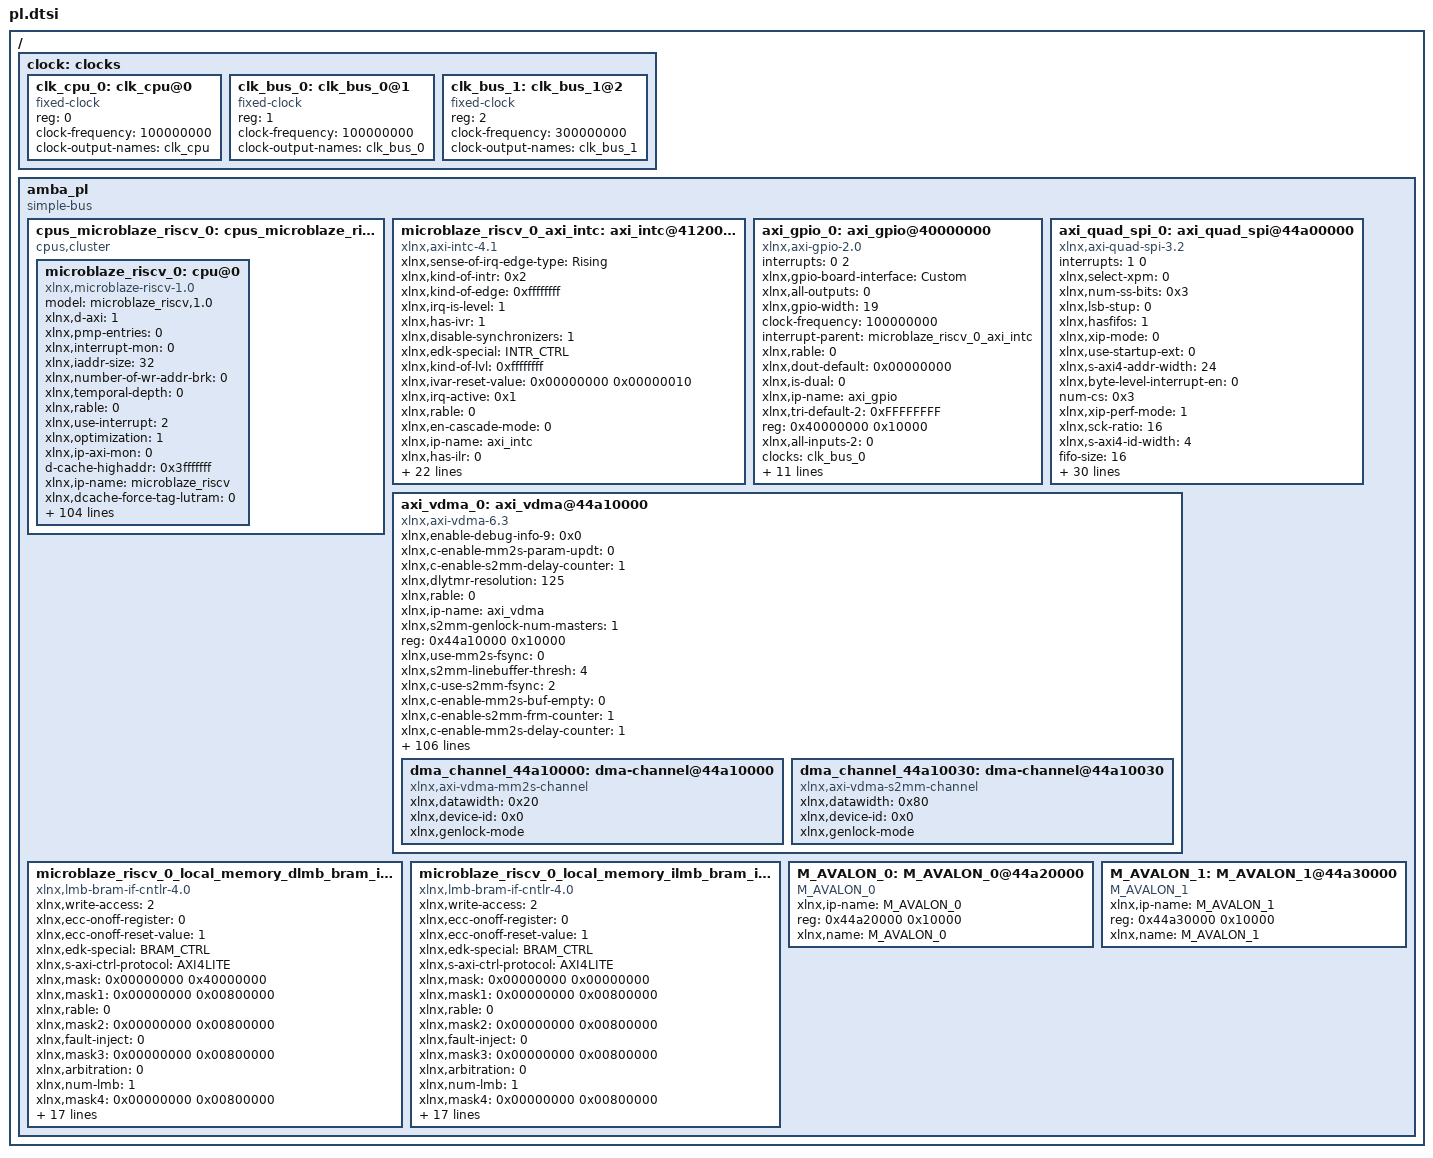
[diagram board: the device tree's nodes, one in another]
/ {
	clock: clocks {
		#address-cells = <1>;
		#size-cells = <0>;
		clk_cpu_0: clk_cpu@0 {
			compatible = "fixed-clock";
			reg = <0>;
			clock-frequency = <100000000>;
			clock-output-names = "clk_cpu";
			#clock-cells = <0>;
		};
		clk_bus_0: clk_bus_0@1 {
			compatible = "fixed-clock";
			reg = <1>;
			clock-frequency = <100000000>;
			clock-output-names = "clk_bus_0";
			#clock-cells = <0>;
		};
		clk_bus_1: clk_bus_1@2 {
			compatible = "fixed-clock";
			reg = <2>;
			clock-frequency = <300000000>;
			clock-output-names = "clk_bus_1";
			#clock-cells = <0>;
		};
	};
	amba_pl: amba_pl {
		ranges;
		compatible = "simple-bus";
		#address-cells = <1>;
		#size-cells = <1>;
		cpus_microblaze_riscv_0: cpus_microblaze_riscv@0 {
			#cpu-mask-cells = <1>;
			compatible = "cpus,cluster";
			#address-cells = <1>;
			#size-cells = <0>;
			microblaze_riscv_0: cpu@0 {
				model = "microblaze_riscv,1.0";
				xlnx,d-axi = <1>;
				xlnx,pmp-entries = <0>;
				xlnx,interrupt-mon = <0>;
				xlnx,iaddr-size = <32>;
				xlnx,number-of-wr-addr-brk = <0>;
				xlnx,temporal-depth = <0>;
				xlnx,rable = <0>;
				xlnx,use-interrupt = <2>;
				xlnx,optimization = <1>;
				xlnx,ip-axi-mon = <0>;
				d-cache-highaddr = <0x3fffffff>;
				xlnx,ip-name = "microblaze_riscv";
				xlnx,dcache-force-tag-lutram = <0>;
				xlnx,pc-width = <15>;
				xlnx,interrupt-is-edge = <0>;
				reg = <0x0>;
				xlnx,async-interrupt = <1>;
				xlnx,use-mmu = <0>;
				xlnx,icache-victims = <0>;
				xlnx,use-bitman-a = <0>;
				xlnx,d-lmb-mon = <0>;
				xlnx,d-lmb-protocol = <0>;
				xlnx,use-bitman-b = <0>;
				xlnx,use-bitman-c = <0>;
				xlnx,dc-axi-mon = <0>;
				xlnx,debug-trace-async-reset = <0>;
				xlnx,trace = <0>;
				xlnx,part = "xcau25p-ffvb676-2-e";
				xlnx,use-config-reset = <0>;
				xlnx,i-lmb-mon = <0>;
				xlnx,dcache-byte-size = <4096>;
				xlnx,ill-instr-exception = <2>;
				compatible = "xlnx,microblaze-riscv-1.0" , "xlnx,microblaze_riscv";
				xlnx,data-size = <32>;
				xlnx,fault-tolerant = <1>;
				xlnx,use-sleep = <0>;
				xlnx,debug-trace-size = <8192>;
				xlnx,pmp-granularity = <2>;
				xlnx,mmu-privileged-instr = <0>;
				d-cache-line-size = <16>;
				xlnx,d-lmb = <1>;
				xlnx,enable-discrete-ports = <0>;
				clock-frequency = <100000000>;
				xlnx,debug-interface = <0>;
				xlnx,use-ext-brk = <0>;
				xlnx,daddr-size = <32>;
				xlnx,debug-enabled = <1>;
				xlnx,num-sync-ff-dbg-trace-clk = <2>;
				xlnx,i-lmb-protocol = <0>;
				xlnx,fsl-exception = <0>;
				xlnx,use-extended-fsl-instr = <0>;
				xlnx,dp-axi-mon = <0>;
				xlnx,impid = <0x00000000 0x00000001>;
				xlnx,branch-target-cache-size = <0>;
				xlnx,dcache-use-writeback = <0>;
				xlnx,use-bitman-s = <0>;
				bus-handle = <&amba_pl>;
				xlnx,icache-line-len = <4>;
				xlnx,base-vectors = <0x00000000 0x00000000>;
				xlnx,ecc-use-ce-exception = <0>;
				xlnx,use-dcache = <0>;
				xlnx,use-barrel = <1>;
				xlnx,edk-special = "microblaze_riscv";
				xlnx,use-muldiv = <2>;
				xlnx,addr-size = <32>;
				xlnx,debug-external-trace = <0>;
				xlnx,piaddr-size = <32>;
				xlnx,misaligned-exceptions = <1>;
				xlnx,use-bitman = <0>;
				xlnx,num-sync-ff-clk-debug = <2>;
				xlnx,debug-event-counters = <0>;
				xlnx,use-atomic = <0>;
				xlnx,i-axi = <0>;
				xlnx,icache-streams = <0>;
				xlnx,g-template-list = <1>;
				xlnx,dcache-line-len = <4>;
				xlnx,num-sync-ff-clk = <2>;
				xlnx,num-sync-ff-dbg-clk = <1>;
				xlnx,interconnect = <2>;
				xlnx,hartid = <0x00000000 0x00000000>;
				xlnx,debug-latency-counters = <0>;
				xlnx,edk-iptype = "PROCESSOR";
				xlnx,use-fpu = <0>;
				xlnx,icache-byte-size = <8192>;
				xlnx,edge-is-positive = <1>;
				xlnx,use-icache = <0>;
				d-cache-size = <4096>;
				xlnx,async-wakeup = <3>;
				xlnx,use-non-secure = <0>;
				xlnx,number-of-rd-addr-brk = <0>;
				d-cache-baseaddr = <0x00000000>;
				xlnx,use-compression = <1>;
				xlnx,avoid-primitives = <0>;
				xlnx,use-counters = <1>;
				xlnx,lockstep-slave = <0>;
				xlnx,use-ext-nm-brk = <0>;
				xlnx,pdaddr-size = <32>;
				xlnx,instr-size = <32>;
				interrupt-handle = <&microblaze_riscv_0_axi_intc>;
				xlnx,i-lmb = <1>;
				xlnx,lockstep-select = <0>;
				xlnx,lmb-data-size = <32>;
				xlnx,ic-axi-mon = <0>;
				xlnx,num-sync-ff-clk-irq = <1>;
				xlnx,fsl-links = <0>;
				timebase-frequency = <100000000>;
				xlnx,archid = <0x00000000 0x00000001>;
				xlnx,icache-force-tag-lutram = <0>;
				xlnx,dcache-data-width = <0>;
				xlnx,dcache-victims = <0>;
				xlnx,use-branch-target-cache = <0>;
				xlnx,debug-profile-size = <0>;
				xlnx,lockstep-master = <0>;
				xlnx,freq = <100000000>;
				xlnx,number-of-pc-brk = <1>;
				xlnx,imprecise-exceptions = <0>;
				xlnx,icache-data-width = <0>;
				xlnx,debug-counter-width = <64>;
			};
		};
		microblaze_riscv_0_axi_intc: axi_intc@41200000 {
			#interrupt-cells = <2>;
			xlnx,sense-of-irq-edge-type = "Rising";
			xlnx,kind-of-intr = <0x2>;
			xlnx,kind-of-edge = <0xffffffff>;
			xlnx,irq-is-level = <1>;
			xlnx,has-ivr = <1>;
			compatible = "xlnx,axi-intc-4.1" , "xlnx,xps-intc-1.00.a";
			xlnx,disable-synchronizers = <1>;
			xlnx,edk-special = "INTR_CTRL";
			xlnx,kind-of-lvl = <0xffffffff>;
			xlnx,ivar-reset-value = <0x00000000 0x00000010>;
			xlnx,irq-active = <0x1>;
			xlnx,rable = <0>;
			xlnx,en-cascade-mode = <0>;
			xlnx,ip-name = "axi_intc";
			xlnx,has-ilr = <0>;
			reg = <0x41200000 0x10000>;
			xlnx,addr-width = <0x20>;
			xlnx,s-axi-aclk-freq-mhz = <100>;
			xlnx,num-sw-intr = <0>;
			xlnx,irq-connection = <0>;
			xlnx,num-intr-inputs = <0x2>;
			xlnx,has-sie = <1>;
			xlnx,has-cie = <1>;
			xlnx,enable-async = <0>;
			xlnx,num-sync-ff = <2>;
			xlnx,mb-clk-not-connected = <1>;
			xlnx,has-ipr = <1>;
			xlnx,edk-iptype = "PERIPHERAL";
			xlnx,sense-of-irq-level-type = "Active_High";
			xlnx,cascade-master = <0>;
			xlnx,processor-clk-freq-mhz = <100>;
			status = "okay";
			xlnx,is-fast = <0x1>;
			xlnx,has-fast = <1>;
			xlnx,ivar-rst-val = <0x0000000000000010>;
			interrupt-controller;
			xlnx,async-intr = <0xFFFFFFFC>;
			xlnx,name = "microblaze_riscv_0_axi_intc";
		};
		axi_gpio_0: axi_gpio@40000000 {
			#interrupt-cells = <2>;
			interrupts = < 0 2 >;
			xlnx,gpio-board-interface = "Custom";
			compatible = "xlnx,axi-gpio-2.0" , "xlnx,xps-gpio-1.00.a";
			xlnx,all-outputs = <0>;
			#gpio-cells = <2>;
			xlnx,gpio-width = <19>;
			clock-frequency = <100000000>;
			interrupt-parent = <&microblaze_riscv_0_axi_intc>;
			xlnx,rable = <0>;
			xlnx,dout-default = <0x00000000>;
			xlnx,is-dual = <0>;
			xlnx,ip-name = "axi_gpio";
			xlnx,tri-default-2 = <0xFFFFFFFF>;
			reg = <0x40000000 0x10000>;
			xlnx,all-inputs-2 = <0>;
			clocks = <&clk_bus_0>;
			xlnx,all-outputs-2 = <0>;
			gpio-controller;
			xlnx,interrupt-present = <1>;
			xlnx,gpio2-board-interface = "Custom";
			xlnx,edk-iptype = "PERIPHERAL";
			xlnx,dout-default-2 = <0x00000000>;
			xlnx,gpio2-width = <32>;
			status = "okay";
			clock-names = "s_axi_aclk";
			interrupt-controller;
			interrupt-names = "ip2intc_irpt";
			xlnx,tri-default = <0x0007E594>;
			xlnx,name = "axi_gpio_0";
			xlnx,all-inputs = <0>;
		};
		axi_quad_spi_0: axi_quad_spi@44a00000 {
			interrupts = < 1 0 >;
			xlnx,select-xpm = <0>;
			xlnx,num-ss-bits = <0x3>;
			compatible = "xlnx,axi-quad-spi-3.2" , "xlnx,xps-spi-2.00.a";
			xlnx,lsb-stup = <0>;
			xlnx,hasfifos = <1>;
			xlnx,xip-mode = <0>;
			xlnx,use-startup-ext = <0>;
			xlnx,s-axi4-addr-width = <24>;
			xlnx,byte-level-interrupt-en = <0>;
			num-cs = <0x3>;
			xlnx,xip-perf-mode = <1>;
			xlnx,sck-ratio = <16>;
			xlnx,s-axi4-id-width = <4>;
			fifo-size = <16>;
			interrupt-parent = <&microblaze_riscv_0_axi_intc>;
			xlnx,rable = <0>;
			xlnx,multiples16 = <1>;
			xlnx,master-mode = <1>;
			xlnx,shared-startup = <0>;
			xlnx,ip-name = "axi_quad_spi";
			xlnx,qspi-board-interface = "Custom";
			xlnx,new-seq-en = <1>;
			reg = <0x44a00000 0x10000>;
			xlnx,dual-quad-mode = <0>;
			bits-per-word = <8>;
			xlnx,num-transfer-bits = <8>;
			xlnx,spi-memory = <1>;
			xlnx,s-axi4-data-width = <32>;
			xlnx,edk-iptype = "PERIPHERAL";
			xlnx,slaveonly = <0>;
			xlnx,use-startup-int = <0>;
			xlnx,use-startup = <0>;
			xlnx,type-of-axi4-interface = <0>;
			xlnx,async-clk = <0>;
			xlnx,spi-mode = <0>;
			xlnx,sck-ratio1 = <1>;
			status = "okay";
			xlnx,fifo-depth = <16>;
			xlnx,uc-family = <1>;
			xlnx,spi-mem-addr-bits = <24>;
			xlnx,axi-interface = <0>;
			interrupt-names = "ip2intc_irpt";
			xlnx,Axi4-address = <0>;
			xlnx,sub-family = "kintexuplus";
			xlnx,name = "axi_quad_spi_0";
			xlnx,fifo-included = <1>;
		};
		axi_vdma_0: axi_vdma@44a10000 {
			xlnx,enable-debug-info-9 = <0x0>;
			xlnx,c-enable-mm2s-param-updt = <0>;
			xlnx,c-enable-s2mm-delay-counter = <1>;
			xlnx,dlytmr-resolution = <125>;
			xlnx,rable = <0>;
			xlnx,ip-name = "axi_vdma";
			xlnx,s2mm-genlock-num-masters = <1>;
			reg = <0x44a10000 0x10000>;
			xlnx,use-mm2s-fsync = <0>;
			xlnx,s2mm-linebuffer-thresh = <4>;
			xlnx,c-use-s2mm-fsync = <2>;
			xlnx,c-enable-mm2s-buf-empty = <0>;
			xlnx,c-enable-s2mm-frm-counter = <1>;
			xlnx,c-enable-mm2s-delay-counter = <1>;
			xlnx,c-dlytmr-resolution = <125>;
			xlnx,c-enable-s2mm-buf-full = <0>;
			xlnx,dynamic-resolution = <1>;
			xlnx,s2mm-sof-enable = <0x1>;
			xlnx,mm2s-genlock-num-masters = <1>;
			xlnx,c-s2mm-genlock-num-masters = <1>;
			xlnx,c-enable-s2mm-fsync-out = <0>;
			xlnx,mm2s-linebuffer-thresh = <4>;
			xlnx,c-use-mm2s-fsync = <0>;
			xlnx,c-s2mm-linebuffer-thresh = <4>;
			xlnx,c-enable-mm2s-frm-counter = <1>;
			compatible = "xlnx,axi-vdma-6.3" , "xlnx,axi-vdma-1.00.a";
			xlnx,c-m-axis-mm2s-tdata-width = <32>;
			clock-frequency = <100000000 300000000 300000000 300000000 300000000>;
			xlnx,c-enable-all = <0>;
			xlnx,s2mm-max-burst-length = <8>;
			xlnx,c-dynamic-resolution = <1>;
			xlnx,c-enable-s2mm-rst-out = <0>;
			xlnx,mm2s-sof-enable = <1>;
			xlnx,include-s2mm-dre = <0x0>;
			xlnx,c-s2mm-sof-enable = <1>;
			xlnx,c-enable-mm2s-fsync-out = <0>;
			xlnx,c-mm2s-genlock-num-masters = <1>;
			xlnx,c-mm2s-linebuffer-thresh = <4>;
			xlnx,c-enable-tstvec = <0>;
			xlnx,mm2s-max-burst-length = <8>;
			xlnx,c-s2mm-max-burst-length = <8>;
			status = "okay";
			xlnx,c-enable-mm2s-rst-out = <0>;
			xlnx,include-mm2s-dre = <0x0>;
			xlnx,c-include-s2mm-dre = <0>;
			xlnx,c-mm2s-sof-enable = <1>;
			xlnx,name = "axi_vdma_0";
			xlnx,c-enable-s2mm-frmstr-reg = <0>;
			xlnx,c-include-sg = <0>;
			xlnx,flush-on-fsync = <0x1>;
			xlnx,c-m-axi-s2mm-data-width = <128>;
			xlnx,c-enable-s2mm-sts-reg = <1>;
			xlnx,include-s2mm-sf = <1>;
			xlnx,c-mm2s-max-burst-length = <8>;
			xlnx,s2mm-linebuffer-depth = <0x200>;
			xlnx,include-s2mm = <0x1>;
			xlnx,c-include-mm2s-dre = <0>;
			clocks = <&clk_bus_0 &clk_bus_1 &clk_bus_1 &clk_bus_1 &clk_bus_1>;
			xlnx,c-enable-mm2s-frmstr-reg = <0>;
			xlnx,enable-debug-info-10 = <0>;
			xlnx,addrwidth = <0x20>;
			xlnx,enable-debug-info-11 = <0>;
			xlnx,enable-debug-info-12 = <1>;
			xlnx,edk-iptype = "PERIPHERAL";
			xlnx,c-flush-on-fsync = <1>;
			xlnx,c-m-axi-mm2s-data-width = <64>;
			xlnx,use-fsync = <1>;
			xlnx,s2mm-genlock-repeat-en = <1>;
			xlnx,enable-vert-flip = <0x0>;
			xlnx,enable-debug-info-13 = <0x0>;
			xlnx,include-mm2s-sf = <0>;
			xlnx,include-internal-genlock = <0x1>;
			xlnx,enable-debug-info-14 = <0x1>;
			xlnx,c-include-s2mm-sf = <1>;
			clock-names = "s_axi_lite_aclk" , "m_axi_mm2s_aclk" , "m_axi_mm2s_aclk" , "m_axi_s2mm_aclk" , "m_axi_s2mm_aclk";
			xlnx,enable-debug-info-15 = <0x1>;
			xlnx,mm2s-linebuffer-depth = <0x200>;
			xlnx,include-mm2s = <0x1>;
			xlnx,c-single-interface = <0>;
			xlnx,c-s2mm-linebuffer-depth = <512>;
			xlnx,c-addr-width = <32>;
			xlnx,c-include-s2mm = <1>;
			xlnx,s2mm-genlock-mode = <0x2>;
			xlnx,c-s-axis-s2mm-tdata-width = <128>;
			xlnx,flush-fsync = <0x1>;
			xlnx,select-xpm = <0>;
			xlnx,s2mm-data-width = <0x80>;
			xlnx,num-fstores = <0x3>;
			xlnx,enable-vidparam-reads = <0x1>;
			xlnx,mm2s-genlock-repeat-en = <0>;
			xlnx,c-use-fsync = <1>;
			xlnx,c-s2mm-genlock-repeat-en = <1>;
			xlnx,c-enable-vert-flip = <0>;
			xlnx,prmry-is-aclk-async = <1>;
			xlnx,c-include-internal-genlock = <1>;
			xlnx,c-include-mm2s-sf = <0>;
			xlnx,s2mm-tdata-width = <0x80>;
			xlnx,enable-vidprmtr-reads = <1>;
			xlnx,c-include-mm2s = <1>;
			xlnx,c-mm2s-linebuffer-depth = <512>;
			xlnx,mm2s-genlock-mode = <0x3>;
			xlnx,enable-debug-info-0 = <0>;
			xlnx,enable-debug-all = <0x0>;
			xlnx,c-s2mm-genlock-mode = <2>;
			xlnx,enable-debug-info-1 = <0x0>;
			xlnx,mm2s-data-width = <0x40>;
			xlnx,enable-debug-info-2 = <0>;
			xlnx,c-enable-s2mm-param-updt = <0>;
			xlnx,c-num-fstores = <3>;
			xlnx,enable-debug-info-3 = <0>;
			xlnx,enable-debug-info-4 = <0>;
			xlnx,c-mm2s-genlock-repeat-en = <0>;
			xlnx,enable-debug-info-5 = <0x0>;
			xlnx,c-prmry-is-aclk-async = <1>;
			xlnx,mm2s-tdata-width = <0x20>;
			xlnx,enable-debug-info-6 = <0x1>;
			xlnx,enable-debug-info-7 = <0x1>;
			xlnx,c-enable-vidprmtr-reads = <1>;
			xlnx,use-s2mm-fsync = <2>;
			xlnx,enable-debug-info-8 = <0>;
			xlnx,c-mm2s-genlock-mode = <3>;
			dma_channel_44a10000: dma-channel@44a10000 {
				xlnx,datawidth = <0x20>;
				xlnx,device-id = <0x0>;
				compatible = "xlnx,axi-vdma-mm2s-channel";
				xlnx,genlock-mode;
			};
			dma_channel_44a10030: dma-channel@44a10030 {
				xlnx,datawidth = <0x80>;
				xlnx,device-id = <0x0>;
				compatible = "xlnx,axi-vdma-s2mm-channel";
				xlnx,genlock-mode;
			};
		};
		microblaze_riscv_0_local_memory_dlmb_bram_if_cntlr: lmb_bram_if_cntlr@0 {
			xlnx,write-access = <2>;
			compatible = "xlnx,lmb-bram-if-cntlr-4.0";
			xlnx,ecc-onoff-register = <0>;
			xlnx,ecc-onoff-reset-value = <1>;
			xlnx,edk-special = "BRAM_CTRL";
			xlnx,s-axi-ctrl-protocol = "AXI4LITE";
			xlnx,mask = <0x00000000 0x40000000>;
			xlnx,mask1 = <0x00000000 0x00800000>;
			xlnx,rable = <0>;
			xlnx,mask2 = <0x00000000 0x00800000>;
			xlnx,fault-inject = <0>;
			xlnx,mask3 = <0x00000000 0x00800000>;
			xlnx,arbitration = <0>;
			xlnx,num-lmb = <1>;
			xlnx,mask4 = <0x00000000 0x00800000>;
			reg = <0x00000000 0x8000>;
			xlnx,s-axi-ctrl-addr-width = <32>;
			xlnx,mask5 = <0x00000000 0x00800000>;
			xlnx,ecc-status-registers = <0>;
			xlnx,mask6 = <0x00000000 0x00800000>;
			xlnx,lmb-protocol = <0>;
			xlnx,ce-counter-width = <0>;
			xlnx,mask7 = <0x00000000 0x00800000>;
			xlnx,ecc = <1>;
			xlnx,lmb-dwidth = <32>;
			xlnx,interconnect = <0>;
			xlnx,ce-failing-registers = <0>;
			xlnx,edk-iptype = "PERIPHERAL";
			xlnx,ue-failing-registers = <0>;
			xlnx,s-axi-ctrl-data-width = <32>;
			xlnx,bram-awidth = <32>;
			xlnx,lmb-awidth = <32>;
		};
		microblaze_riscv_0_local_memory_ilmb_bram_if_cntlr: lmb_bram_if_cntlr@1 {
			xlnx,write-access = <2>;
			compatible = "xlnx,lmb-bram-if-cntlr-4.0";
			xlnx,ecc-onoff-register = <0>;
			xlnx,ecc-onoff-reset-value = <1>;
			xlnx,edk-special = "BRAM_CTRL";
			xlnx,s-axi-ctrl-protocol = "AXI4LITE";
			xlnx,mask = <0x00000000 0x00000000>;
			xlnx,mask1 = <0x00000000 0x00800000>;
			xlnx,rable = <0>;
			xlnx,mask2 = <0x00000000 0x00800000>;
			xlnx,fault-inject = <0>;
			xlnx,mask3 = <0x00000000 0x00800000>;
			xlnx,arbitration = <0>;
			xlnx,num-lmb = <1>;
			xlnx,mask4 = <0x00000000 0x00800000>;
			reg = <0x00000000 0x8000>;
			xlnx,s-axi-ctrl-addr-width = <32>;
			xlnx,mask5 = <0x00000000 0x00800000>;
			xlnx,ecc-status-registers = <0>;
			xlnx,mask6 = <0x00000000 0x00800000>;
			xlnx,lmb-protocol = <0>;
			xlnx,ce-counter-width = <0>;
			xlnx,mask7 = <0x00000000 0x00800000>;
			xlnx,ecc = <1>;
			xlnx,lmb-dwidth = <32>;
			xlnx,interconnect = <0>;
			xlnx,ce-failing-registers = <0>;
			xlnx,edk-iptype = "PERIPHERAL";
			xlnx,ue-failing-registers = <0>;
			xlnx,s-axi-ctrl-data-width = <32>;
			xlnx,bram-awidth = <32>;
			xlnx,lmb-awidth = <32>;
		};
		M_AVALON_0: M_AVALON_0@44a20000 {
			status = "okay";
			compatible = "M_AVALON_0";
			xlnx,ip-name = "M_AVALON_0";
			reg = <0x44a20000 0x10000>;
			xlnx,name = "M_AVALON_0";
		};
		M_AVALON_1: M_AVALON_1@44a30000 {
			status = "okay";
			compatible = "M_AVALON_1";
			xlnx,ip-name = "M_AVALON_1";
			reg = <0x44a30000 0x10000>;
			xlnx,name = "M_AVALON_1";
		};
	};
};
